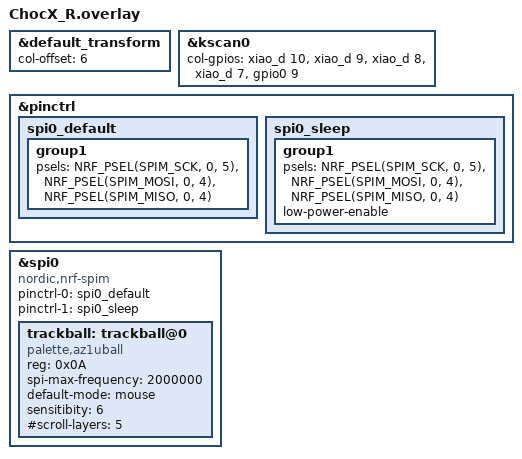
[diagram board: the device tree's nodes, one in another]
// This file was generated from a template. Edit it to match your keyboard.
// See https://zmk.dev/docs/development/hardware-integration/new-shield for more
// instructions.

#include "ChocX.dtsi"

&default_transform {
    col-offset = <6>;
};

&kscan0 {
        col-gpios
            = <&xiao_d 10 GPIO_ACTIVE_HIGH>
            , <&xiao_d 9 GPIO_ACTIVE_HIGH> 
            , <&xiao_d 8 GPIO_ACTIVE_HIGH> 
            , <&xiao_d 7 GPIO_ACTIVE_HIGH> 
            , <&gpio0 9 GPIO_ACTIVE_HIGH>
            ;
};

&pinctrl {
    spi0_default: spi0_default {
        group1 {
            psels = <NRF_PSEL(SPIM_SCK, 0, 5)>,
                <NRF_PSEL(SPIM_MOSI, 0, 4)>,
                <NRF_PSEL(SPIM_MISO, 0, 4)>;
        };
    };

    spi0_sleep: spi0_sleep {
        group1 {
            psels = <NRF_PSEL(SPIM_SCK, 0, 5)>,
                <NRF_PSEL(SPIM_MOSI, 0, 4)>,
                <NRF_PSEL(SPIM_MISO, 0, 4)>;
            low-power-enable;
        };
    };
};

&spi0 {
    status = "okay";
    compatible = "nordic,nrf-spim";
    pinctrl-0 = <&spi0_default>;
    pinctrl-1 = <&spi0_sleep>;
    pinctrl-names = "default", "sleep";

    trackball: trackball@0 {
        status = "okay";
        compatible = "palette,az1uball";
        reg = <0x0A>;
        spi-max-frequency = <2000000>;
        default-mode = "mouse";
        sensitibity = "4x"
        #automouse-layer = <6>;
        #scroll-layers = <5>;
    };
};
